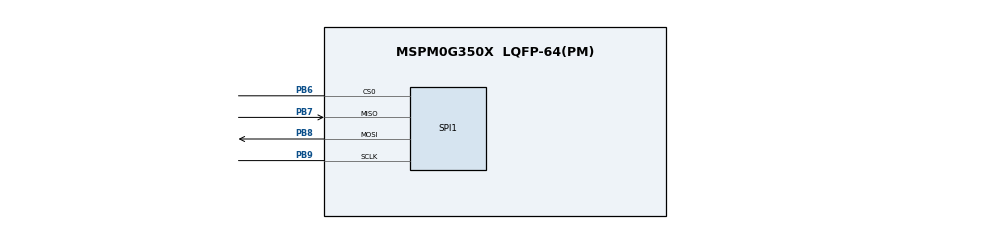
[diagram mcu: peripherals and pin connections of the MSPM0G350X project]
/**
 * @cliArgs --device "MSPM0G350X" --part "Default" --package "LQFP-64(PM)" --product "mspm0_sdk@2.07.00.05"
 * @versions {"tool":"1.25.0+4268"}
 */

/**
 * Import the modules used in this configuration.
 */
const GPIO   = scripting.addModule("/ti/driverlib/GPIO", {}, false);
const GPIO1  = GPIO.addInstance();
const GPIO2  = GPIO.addInstance();
const SPI    = scripting.addModule("/ti/driverlib/SPI", {}, false);
const SPI1   = SPI.addInstance();
const SYSCTL = scripting.addModule("/ti/driverlib/SYSCTL");

/**
 * Write custom configuration values to the imported modules.
 */
GPIO1.$name                                 = "GPIO_LEDS";
GPIO1.port                                  = "PORTA";
GPIO1.associatedPins.create(2);
GPIO1.associatedPins[0].$name               = "USER_LED_1";
GPIO1.associatedPins[0].assignedPortSegment = "Lower";
GPIO1.associatedPins[0].assignedPin         = "0";
GPIO1.associatedPins[0].initialValue        = "SET";
GPIO1.associatedPins[1].$name               = "USER_TEST";
GPIO1.associatedPins[1].assignedPortSegment = "Lower";
GPIO1.associatedPins[1].assignedPin         = "15";
GPIO1.associatedPins[1].initialValue        = "SET";

const Board = scripting.addModule("/ti/driverlib/Board", {}, false);

GPIO2.$name                          = "EXTRA";
GPIO2.associatedPins.create(3);
GPIO2.associatedPins[0].$name        = "RST";
GPIO2.associatedPins[0].assignedPort = "PORTA";
GPIO2.associatedPins[0].assignedPin  = "22";
GPIO2.associatedPins[1].$name        = "DC";
GPIO2.associatedPins[1].assignedPort = "PORTA";
GPIO2.associatedPins[1].assignedPin  = "13";
GPIO2.associatedPins[2].$name        = "CS";
GPIO2.associatedPins[2].assignedPort = "PORTB";
GPIO2.associatedPins[2].assignedPin  = "15";

SPI1.$name                      = "SPI_0";
SPI1.peripheralChipSelect       = "1";
SPI1.targetBitRate              = 16000000;
SPI1.peripheral.$assign         = "SPI1";
SPI1.peripheral.sclkPin.$assign = "PB9";
SPI1.peripheral.mosiPin.$assign = "PB8";
SPI1.peripheral.misoPin.$assign = "PB7";
SPI1.peripheral.cs0Pin.$assign  = "PB6";
SPI1.sclkPinConfig.$name        = "ti_driverlib_gpio_GPIOPinGeneric0";
SPI1.mosiPinConfig.$name        = "ti_driverlib_gpio_GPIOPinGeneric1";
SPI1.misoPinConfig.$name        = "ti_driverlib_gpio_GPIOPinGeneric2";
SPI1.cs0PinConfig.$name         = "ti_driverlib_gpio_GPIOPinGeneric3";

SYSCTL.forceDefaultClkConfig = true;
SYSCTL.clockTreeEn           = true;

/**
 * Pinmux solution for unlocked pins/peripherals. This ensures that minor changes to the automatic solver in a future
 * version of the tool will not impact the pinmux you originally saw.  These lines can be completely deleted in order to
 * re-solve from scratch.
 */
GPIO1.associatedPins[0].pin.$suggestSolution = "PA0";
GPIO1.associatedPins[1].pin.$suggestSolution = "PA15";
Board.peripheral.$suggestSolution            = "DEBUGSS";
Board.peripheral.swclkPin.$suggestSolution   = "PA20";
Board.peripheral.swdioPin.$suggestSolution   = "PA19";
GPIO2.associatedPins[0].pin.$suggestSolution = "PA22";
GPIO2.associatedPins[1].pin.$suggestSolution = "PA13";
GPIO2.associatedPins[2].pin.$suggestSolution = "PB15";
